# STM32MP13xx register map
File version: 1.5
CPU: CA7 r0p0, little endian, MPU, FPU, 4 interrupt priority bits
Registers are 32-bit, read-write, reset 0x0 unless marked. A register's access mark holds for its fields unless they carry their own. Offsets are from the block's base; [hi:lo] are bit positions; {n}, {i} and the like mark numbered series; 'fields as' and 'values as' point back to an identical list.

## TZC
Base 0x5C006000
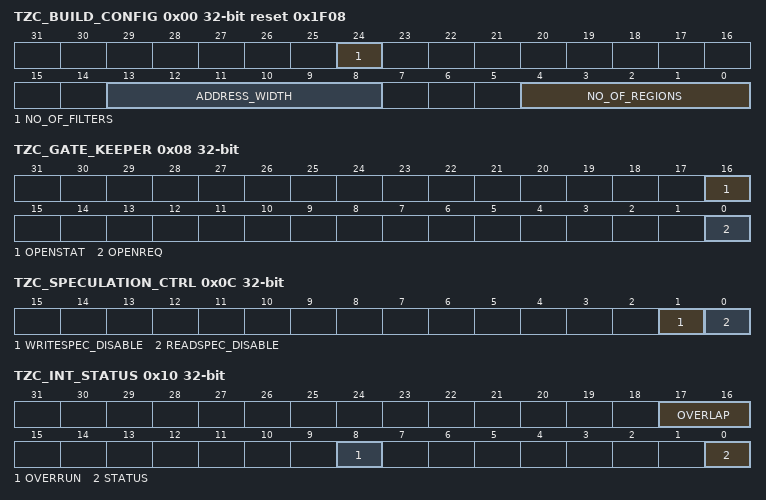
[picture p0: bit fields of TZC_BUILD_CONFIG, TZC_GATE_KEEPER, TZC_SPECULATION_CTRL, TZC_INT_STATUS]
0x00 TZC_BUILD_CONFIG ro reset 0x1F08 — TZC configuration register
  [24] NO_OF_FILTERS — Number of filters
    0=1 filter
  [13:8] ADDRESS_WIDTH — Address width Others: Reserved
    31=32-bit address width
  [4:0] NO_OF_REGIONS — Number fo regions Others: Reserved
    8=9 regions
0x04 TZC_ACTION
  [1:0] REACTION_VALUE — Permission failure reaction Controls how TZC signals region permission failure. 2: set tzcint high and issue OKAY on the bus 3: set tzcint high and issue DECERR on the bus
    0=set tzcint low and issue OKAY on the bus; 1=set tzcint low and issue DECERR on the bus
0x08 TZC_GATE_KEEPER access per field
  [16] OPENSTAT ro — Gate keeper status for filter
    0=filter is opened; 1=filter is closed
  [0] OPENREQ rw — Gate keeper open request for filter
    0=request filter to open; 1=request filter to close
0x0C TZC_SPECULATION_CTRL — TZC speculation control register
  [1] WRITESPEC_DISABLE — Write access speculation disable
    0=write access speculation enabled; 1=write access speculation disabled
  [0] READSPEC_DISABLE — Read access speculation disable
    0=read access speculation enabled; 1=read access speculation disabled
0x10 TZC_INT_STATUS ro — TZC interrupt status register
  [all] fields
    0=interrupt is not asserted; 1=interrupt asserted and waiting to be cleared
  [17:16] OVERLAP — Overlap violation for each filter Bit 17 is for filter 1, bit 16 is for filter 0.
  [8] OVERRUN — Permission failure overrun Two or more regions permission failures for the filter.
  [0] STATUS — Interrupt status for the filter.
0x14 TZC_INT_CLEAR wo — TZC interrupt clear register
  [0] CLEAR — Filter interrupt clear Write “1” to clear interrupt for each filter.
0x20 TZC_FAIL_ADDRESS_LOW ro — TZC fail address low register x
  [31:0] ADDR_STATUS_LOW — Fail address low bits Low 32 address bits of the first failed access permission check in the filter.
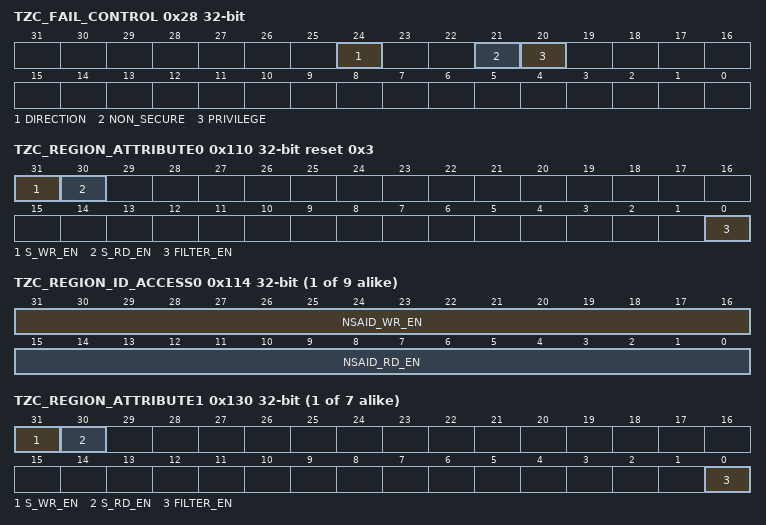
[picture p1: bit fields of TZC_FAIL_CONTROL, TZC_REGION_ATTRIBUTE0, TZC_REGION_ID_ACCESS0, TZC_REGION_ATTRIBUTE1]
0x28 TZC_FAIL_CONTROL ro — TZC fail control register x
  [24] DIRECTION — Access failure direction
    0=Read access failure; 1=Write access failure
  [21] NON_SECURE — Non-secure access failure
    0=Secure access failure; 1=Non-secure access failure
  [20] PRIVILEGE — Privilege access failure
    0=Unprivileged access failure; 1=Privileged access failure
0x2C TZC_FAIL_ID ro — TZC fail ID register x
  [10:0] ID — AXI fail ID Return the AXI ID of the first fail.
0x100 TZC_REGION_BASE_LOW0 ro — TZC region 0 base address low register
  [31:12] BASE_ADDRESS_LOW — base address bits[31:12] for region 0 Others: Reserved
    0=fixed value for region 0
0x108 TZC_REGION_TOP_LOW0 ro reset 0xFFFFFFFF — TZC region 0 top address low register
  [31:12] TOP_ADDRESS_LOW — Top address bits [31:12] of region 0 Others: Reserved
    0xFFFFF=fixed value for region 0
0x110 TZC_REGION_ATTRIBUTE0 access per field reset 0x3 — TZC region 0 attribute register
  [31] S_WR_EN rw — Secure global write enable
    0=secure write to the region are not allowed; 1=permit secure write into the region
  [30] S_RD_EN rw — Secure global read enable
    0=secure read to the region are not allowed; 1=permit secure read into the region
  [0] FILTER_EN ro — Region enable for the filter
    1=enable filter for the region
{0x114+0x20*i} TZC_REGION_ID_ACCESS{i} (i=0..8) — TZC region {i} ID access register
  [31:16] NSAID_WR_EN — Region write enable for each NSAID Bit 16 is associated to NSAID = 0 .. bit 31 is associated to NSAID = 15
    0=forbids write non-secure to the region for this NSAID; 1=permits write non-secure to the region for this NSAID
  [15:0] NSAID_RD_EN — Region read enable for each NSAID Bit 0 is associated to NSAID = 0 ... bit 15 is associated to NSAID = 15.
    0=forbids read non-secure to the region for this NSAID; 1=permits read non-secure to the region for this NSAID
{0x100+0x20*i} TZC_REGION_BASE_LOW{i} (i=1..8) — TZC region {i} base address low register
  [31:12] BASE_ADDRESS_LOW — Base address bits[31:12] for region x
{0x108+0x20*i} TZC_REGION_TOP_LOW{i} reset 0xFFF (i=1..8) — TZC regions {i} top address low register
  [31:12] TOP_ADDRESS_LOW — Top address bits [31:12] of region x
{0x110+0x20*i} TZC_REGION_ATTRIBUTE{i} (i=1..7) — TZC region {i} attribute register
  [31] S_WR_EN — Secure global write enable
    values as TZC_REGION_ATTRIBUTE0.S_WR_EN
  [30] S_RD_EN — Secure global read enable
    values as TZC_REGION_ATTRIBUTE0.S_RD_EN
  [0] FILTER_EN — Region enable for the filter
    0=disable filter for the region; 1=enable filter for the region
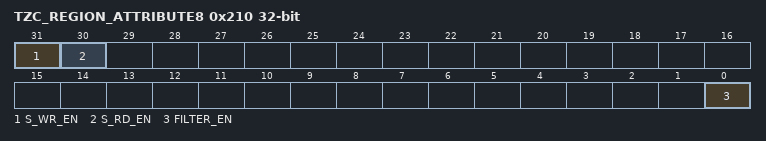
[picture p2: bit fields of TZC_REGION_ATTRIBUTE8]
0x210 TZC_REGION_ATTRIBUTE8 — TZC region 8 attribute register
  [31] S_WR_EN — Secure global write enable
    values as TZC_REGION_ATTRIBUTE0.S_WR_EN
  [30] S_RD_EN — Secure global read enable
  [0] FILTER_EN — Region enable for the filter
    values as TZC_REGION_ATTRIBUTE1.FILTER_EN
0xFD0 TZC_PID4 ro reset 0x4 — TZC peripheral ID 4 register
  [7:0] PER_ID_4 — Peripheral ID 4
{0xFC0+4i} TZC_PID{i} ro (i=5..7) — TZC peripheral ID {i} register
  [7:0] PER_ID_{i} — Peripheral ID {i}
0xFE0 TZC_PID0 ro reset 0x60 — TZC peripheral ID 0 register
  [7:0] PER_ID_0 — Peripheral ID 0
0xFE4 TZC_PID1 ro reset 0xB4 — TZC peripheral ID 1 register
  [7:0] PER_ID_1 — Peripheral ID 1
0xFE8 TZC_PID2 ro reset 0x2B — TZC peripheral ID 2 register
  [7:0] PER_ID_2 — Peripheral ID 2
0xFEC TZC_PID3 ro — TZC peripheral ID 3 register
  [7:0] PER_ID_3 — Peripheral ID 3
0xFF0 TZC_CID0 ro reset 0xD — TZC component ID 0 register
  [7:0] COMP_ID_0 — Component ID 0
0xFF4 TZC_CID1 ro reset 0xF0 — TZC component ID 1 register
  [7:0] COMP_ID_1 — Component ID 0
0xFF8 TZC_CID2 ro reset 0x5 — TZC component ID 2 register
  [7:0] COMP_ID_2 — Component ID 2
0xFFC TZC_CID3 ro reset 0xB1 — TZC component ID 3 register
  [7:0] COMP_ID_3 — Component ID 3
